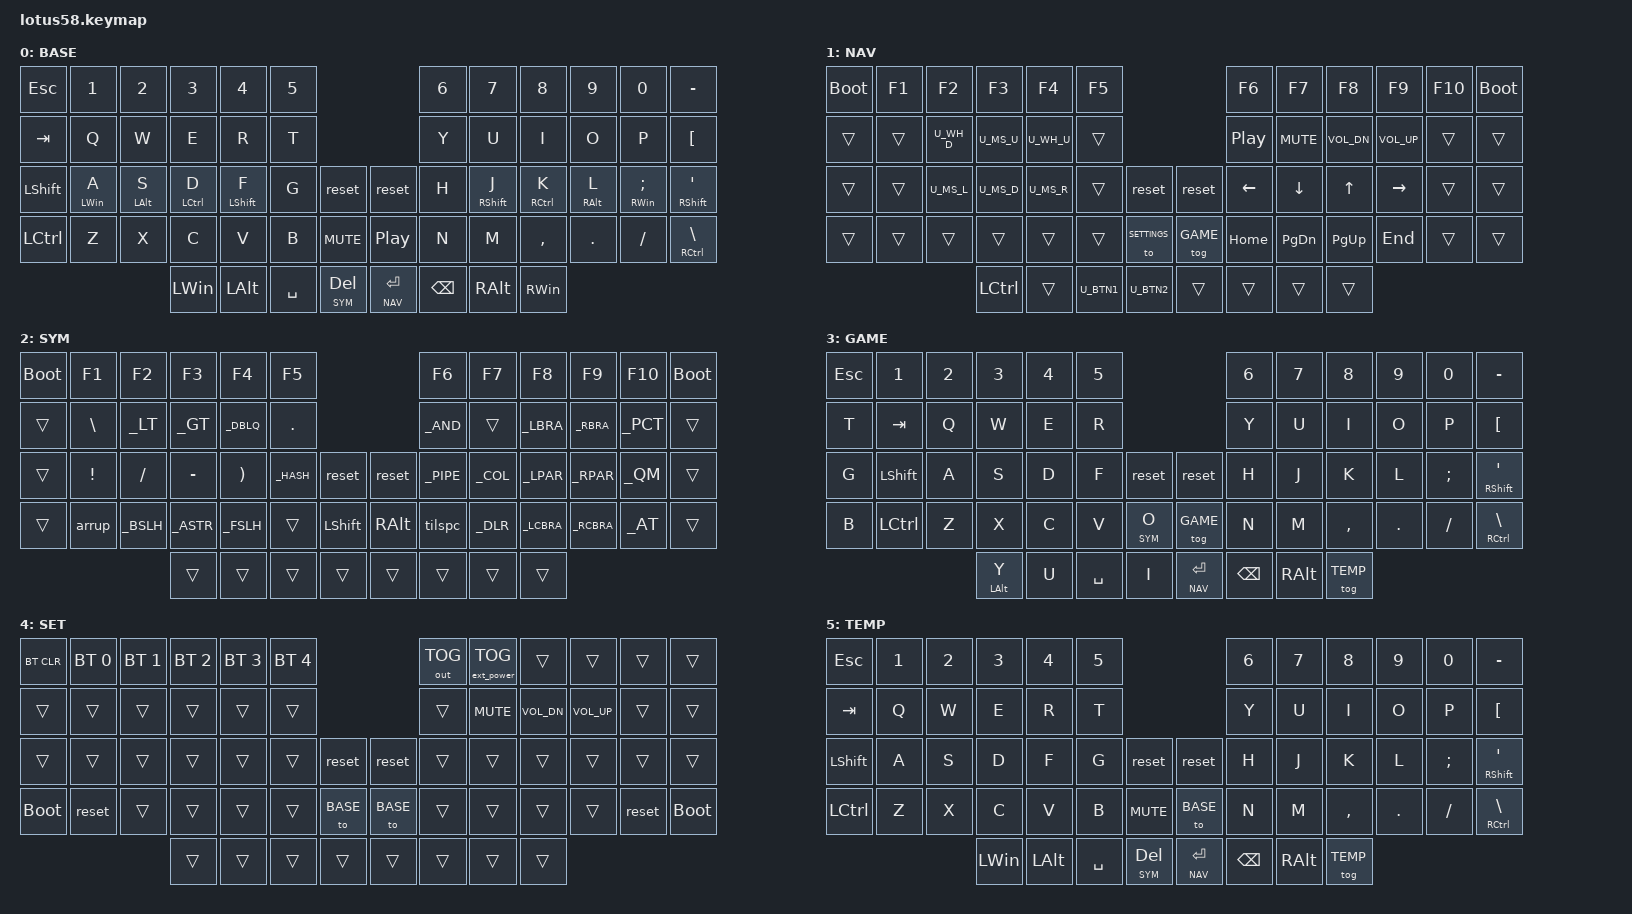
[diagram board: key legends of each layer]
/*
 * Copyright (c) 2022 The ZMK Contributors
 *
 * SPDX-License-Identifier: MIT
 */

#include <behaviors.dtsi>
#include <dt-bindings/zmk/keys.h>
#include <dt-bindings/zmk/bt.h>
#include <dt-bindings/zmk/outputs.h>
#include <dt-bindings/zmk/ext_power.h>

#include "keycodes.h"
#include "keypos.h"

#include "mouse.dtsi"

#define BASE 0
#define NAV 1
#define SYM 2
#define GAME 3
#define SETTINGS 4
#define TEMP 5

/ {
    

    macros {
        arrup: arr_up {
            label = "arr_up";
            compatible = "zmk,behavior-macro";
            #binding-cells = <0>;
            bindings
                = <&macro_tap &kp RBRC>
                , <&macro_tap &kp SPACE>
                ;
        };
        tilspc: tilde_space {
            label = "tilde_space";
            compatible = "zmk,behavior-macro";
            #binding-cells = <0>;
            bindings
                = <&macro_tap &kp _TILDE>
                , <&macro_tap &kp SPACE>
                ;
        };
    };

    behaviors {
        prog_caps: behavior_prog_caps_word {
        compatible = "zmk,behavior-caps-word";
        label = "PROG_CAPS";
        #binding-cells = <0>;
        continue-list = <FSLH LS(FSLH) RS(FSLH)>;
        };
        l_hrm: left_home_row_mod {
            compatible = "zmk,behavior-hold-tap";
            label = "LEFT_HOME_ROW_MOD";
            #binding-cells = <2>;
            flavor = "balanced";
            tapping-term-ms = <280>;
            quick-tap-ms = <175>;
            bindings = <&kp>, <&kp>;
            hold-trigger-key-positions = <MAIN_KEYS_R THUMB_KEYS_L>;
        };
        r_hrm: right_home_row_mod {
            compatible = "zmk,behavior-hold-tap";
            label = "RIGHT_HOME_ROW_MOD";
            #binding-cells = <2>;
            flavor = "balanced";
            tapping-term-ms = <280>;
            quick-tap-ms = <175>;
            bindings = <&kp>, <&kp>;
            hold-trigger-key-positions = <MAIN_KEYS_L THUMB_KEYS_R>;
        };
    };

    combos {
        compatible = "zmk,combos";

        combo_esc {
            timeout-ms = <50>;
            key-positions = <L_1_1 L_1_2>;
            layers = <0>;
            bindings = <&kp ESC>;
        };

        combo_caps_word {
            timeout-ms = <50>;
            key-positions = <L_2_4 R_2_1>;
            layers = <0>;
            bindings = <&prog_caps>;
        };

        combo_ctrl_shft_c {
            timeout-ms = <250>;
            key-positions = <R_2_2 R_2_1 L_3_3>;
            layers = <0>;
            bindings = <&kp LC(LS(C))>;
        };

        combo_ctrl_shft_v {
            timeout-ms = <250>;
            key-positions = <R_2_2 R_2_1 L_3_4>;
            layers = <0>;
            bindings = <&kp LC(LS(V))>;
        };
    };

    keymap {
        compatible = "zmk,keymap";

        base_layer {
            label = "BASE";
            bindings = <
//  _________________________________________________________________________________________________________________________________________________________________________
//  |ESC        |1          |2          |3          |4          |5          |                       |6          |7          |8          |9          |0          |+          |
    &kp ESC     &kp N1      &kp N2      &kp N3      &kp N4      &kp N5                              &kp N6      &kp N7      &kp N8      &kp N9      &kp N0      &kp MINUS
//  |-----------|-----------|-----------|-----------|-----------|-----------|                       |-----------|-----------|-----------|-----------|-----------|-----------|
//  |TAB        |Q          |W          |E          |R          |T          |                       |Y          |U          |I          |O          |P          |Å          |
    &kp TAB     &kp Q       &kp W       &kp E       &kp R       &kp T                               &kp Y       &kp U       &kp I       &kp O       &kp P       &kp LBKT
//  |-----------|-----------|-----------|-----------|-----------|-----------|                       |-----------|-----------|-----------|-----------|-----------|-----------|
//  |SHIFT      |A          |S          |D          |F          |G          |                       |H          |J          |K          |L          |Æ          |Ø          |
    &kp LSHFT   &l_hrm LWIN A       &l_hrm LALT S       &l_hrm LCTRL D       &l_hrm LSHFT F       &kp G       &reset      &reset      &kp H       &r_hrm RSHFT J       &r_hrm RCTRL K       &r_hrm RALT L       &r_hrm RWIN SEMI    &mt RSHFT SQT
//  |-----------|-----------|-----------|-----------|-----------|-----------|-----------|-----------|-----------|-----------|-----------|-----------|-----------|-----------|
//  |CTRL       |Z          |X          |C          |V          |B          |MUTE       |PLAY/PAUSE |N          |M          |,          |.          |-          |'          |
    &kp LCTRL   &kp Z       &kp X       &kp C       &kp V       &kp B       &kp C_MUTE  &kp C_PP    &kp N       &kp M       &kp COMMA   &kp DOT     &kp FSLH    &mt RCTRL BSLH
//  |-----------|-----------|-----------|-----------|-----------|-----------|-----------|-----------|-----------|-----------|-----------|-----------|-----------|-----------|
//                                      |LWIN       |LALT       |SPACE      |SYM + DEL  |NAV + ENTER|BACKSPACE  |RALT       |RWIN       |
                                        &kp LWIN    &kp LALT    &kp SPACE   &lt SYM DEL &lt NAV RET &kp BSPC    &kp RALT    &kp RWIN
//                                      |-----------|-----------|-----------|-----------|-----------|-----------|-----------|-----------|
            >;
        };

        nav_layer {
            label = "NAV";
            bindings = <
//  _________________________________________________________________________________________________________________________________________________________________________
//  |           |F1         |F2         |F3         |F4         |F5         |                       |F6         |F7         |F8         |F9         |F0         |           |
    &bootloader &kp F1      &kp F2      &kp F3      &kp F4      &kp F5                              &kp F6      &kp F7      &kp F8      &kp F9      &kp F10     &bootloader
//  |-----------|-----------|-----------|-----------|-----------|-----------|                       |-----------|-----------|-----------|-----------|-----------|-----------|
//  |           |           |           |^          |           |           |                       |PLAY/PAUSE |MUTE       |VOL DOWN   |VOL UP     |           |           |
    &trans      &trans      U_WH_D      U_MS_U      U_WH_U      &trans                              &kp C_PP    &kp C_MUTE  &kp C_VOL_DN &kp C_VOLUME_UP &trans &trans
//  |-----------|-----------|-----------|-----------|-----------|-----------|                       |-----------|-----------|-----------|-----------|-----------|-----------|
//  |           |           |<-         |v          |->         |           |                       |<-         |v          |^          |->         |           |           |
    &trans      &trans      U_MS_L      U_MS_D      U_MS_R      &trans      &reset      &reset      &kp LEFT    &kp DOWN    &kp UP      &kp RIGHT   &trans      &trans
//  |-----------|-----------|-----------|-----------|-----------|-----------|-----------|-----------|-----------|-----------|-----------|-----------|-----------|-----------|
//  |           |           |           |           |           |           |SETTINGS   |GAME       |HOME       |PAGE DOWN  |PAGE UP    |END        |           |           |
    &trans      &trans      &trans      &trans      &trans      &trans      &to SETTINGS &tog GAME  &kp HOME    &kp PG_DN   &kp PG_UP   &kp END     &trans      &trans
//  |-----------|-----------|-----------|-----------|-----------|-----------|-----------|-----------|-----------|-----------|-----------|-----------|-----------|-----------|
//                                      |CTRL       |           |m1         |m2         |           |           |           |           |
                                        &kp LCTRL   &trans      U_BTN1      U_BTN2      &trans      &trans      &trans      &trans
//                                      |-----------|-----------|-----------|-----------|-----------|-----------|-----------|-----------|
            >;
        };


        sym_layer {
            label = "SYM";
            bindings = <
//  _________________________________________________________________________________________________________________________________________________________________________
//  |           |F1         |F2         |F3         |F4         |F5         |                       |F6         |F7         |F8         |F9         |F0         |           |
    &bootloader &kp F1      &kp F2      &kp F3      &kp F4      &kp F5                              &kp F6      &kp F7      &kp F8      &kp F9      &kp F10     &bootloader
//  |-----------|-----------|-----------|-----------|-----------|-----------|                       |-----------|-----------|-----------|-----------|-----------|-----------|
//  |           |'          |<          |>          |"          |.          |                       |&          |           |(          |)          |%          |           |
    &trans      &kp BSLH    &kp _LT     &kp _GT     &kp _DBLQ   &kp DOT                             &kp _AND    &trans      &kp _LBRA   &kp _RBRA   &kp _PCT    &trans
//  |-----------|-----------|-----------|-----------|-----------|-----------|                       |-----------|-----------|-----------|-----------|-----------|-----------|
//  |           |!          |-          |+          |=          |#          |                       ||          |:          |(          |)          |?          |           |
    &trans      &kp EXCL    &kp FSLH    &kp MINUS   &kp RPAR    &kp _HASH   &reset      &reset      &kp _PIPE   &kp _COL    &kp _LPAR   &kp _RPAR   &kp _QM     &trans
//  |-----------|-----------|-----------|-----------|-----------|-----------|-----------|-----------|-----------|-----------|-----------|-----------|-----------|-----------|
//  |           |^          |/          |*          |\          |           |SHIFT      |RALT       |~          |$          |{          |}          |@          |           |
    &trans      &arrup      &kp _BSLH   &kp _ASTR   &kp _FSLH   &trans      &kp LSHFT   &kp RALT    &tilspc     &kp _DLR    &kp _LCBRA  &kp _RCBRA  &kp _AT     &trans
//  |-----------|-----------|-----------|-----------|-----------|-----------|-----------|-----------|-----------|-----------|-----------|-----------|-----------|-----------|
//                                      |           |           |           |           |           |           |           |           |
                                        &trans      &trans      &trans      &trans      &trans      &trans      &trans      &trans
//                                      |-----------|-----------|-----------|-----------|-----------|-----------|-----------|-----------|
            >;
        };

        game_layer {
            label = "GAME";
            bindings = <
//  _________________________________________________________________________________________________________________________________________________________________________
//  |ESC        |1          |2          |3          |4          |5          |                       |6          |7          |8          |9          |0          |+          |
    &kp ESC     &kp N1      &kp N2      &kp N3      &kp N4      &kp N5                              &kp N6      &kp N7      &kp N8      &kp N9      &kp N0      &kp MINUS
//  |-----------|-----------|-----------|-----------|-----------|-----------|                       |-----------|-----------|-----------|-----------|-----------|-----------|
//  |T          |TAB        |Q          |W          |E          |R          |                       |Y          |U          |I          |O          |P          |Å          |
    &kp T       &kp TAB     &kp Q       &kp W       &kp E       &kp R                               &kp Y       &kp U       &kp I       &kp O       &kp P       &kp LBKT
//  |-----------|-----------|-----------|-----------|-----------|-----------|                       |-----------|-----------|-----------|-----------|-----------|-----------|
//  |G          |SHIFT      |A          |S          |D          |F          |                       |H          |J          |K          |L          |Æ          |Ø          |
    &kp G       &kp LSHFT   &kp A       &kp S       &kp D       &kp F       &reset      &reset      &kp H       &kp J       &kp K       &kp L       &kp SEMI    &mt RSHFT SQT
//  |-----------|-----------|-----------|-----------|-----------|-----------|-----------|-----------|-----------|-----------|-----------|-----------|-----------|-----------|
//  |B          |CTRL       |Z          |X          |C          |V          |O          |BASE       |N          |M          |,          |.          |-          |'          |
    &kp B       &kp LCTRL   &kp Z       &kp X       &kp C       &kp V       &lt SYM O       &tog GAME   &kp N       &kp M       &kp COMMA   &kp DOT     &kp FSLH    &mt RCTRL BSLH
//  |-----------|-----------|-----------|-----------|-----------|-----------|-----------|-----------|-----------|-----------|-----------|-----------|-----------|-----------|
//                                      |LALT + Y   |U          |SPACE      |I          |NAV + ENTER|BACKSPACE  |RALT       |TEMP on    |
                                        &mt LALT Y  &kp U       &kp SPACE   &kp I       &lt NAV RET &kp BSPC    &kp RALT    &tog TEMP
//                                      |-----------|-----------|-----------|-----------|-----------|-----------|-----------|-----------|
            >;
        };

        settings_layer {
            label = "SET";
            bindings = <
//  _________________________________________________________________________________________________________________________________________________________________________
//  |BT clear   |BT 0       |BT 1      |BT 2        |BT 3       |BT 4       |                       |toggle bt/usb|toggle ext power |   |           |           |           |
    &bt BT_CLR &bt BT_SEL 0 &bt BT_SEL 1 &bt BT_SEL 2 &bt BT_SEL 3 &bt BT_SEL 4                     &out OUT_TOG &ext_power EP_TOG &trans &trans    &trans     &trans
//  |-----------|-----------|-----------|-----------|-----------|-----------|                       |-----------|-----------|-----------|-----------|-----------|-----------|
//  |           |           |           |^          |           |           |                       |           |MUTE       |VOL DOWN   |VOL UP     |           |           |
    &trans      &trans      &trans      &trans      &trans      &trans                              &trans      &kp C_MUTE  &kp C_VOL_DN &kp C_VOLUME_UP &trans &trans
//  |-----------|-----------|-----------|-----------|-----------|-----------|                       |-----------|-----------|-----------|-----------|-----------|-----------|
//  |           |           |           |           |           |           |                       |           |           |           |           |           |           |
    &trans      &trans      &trans      &trans      &trans      &trans      &reset      &reset      &trans      &trans      &trans      &trans      &trans      &trans
//  |-----------|-----------|-----------|-----------|-----------|-----------|-----------|-----------|-----------|-----------|-----------|-----------|-----------|-----------|
//  |           |           |           |           |           |           |                       |           |           |           |           |           |           |
    &bootloader &reset      &trans      &trans      &trans      &trans      &to BASE    &to BASE    &trans      &trans      &trans      &trans   &reset      &bootloader
//  |-----------|-----------|-----------|-----------|-----------|-----------|-----------|-----------|-----------|-----------|-----------|-----------|-----------|-----------|
//                                      |           |           |           |           |           |           |           |           |
                                        &trans      &trans      &trans      &trans      &trans      &trans      &trans      &trans
//                                      |-----------|-----------|-----------|-----------|-----------|-----------|-----------|-----------|
            >;
        };

        temp_layer {
            label = "TEMP";
            bindings = <
//  _________________________________________________________________________________________________________________________________________________________________________
//  |ESC        |1          |2          |3          |4          |5          |                       |6          |7          |8          |9          |0          |+          |
    &kp ESC     &kp N1      &kp N2      &kp N3      &kp N4      &kp N5                              &kp N6      &kp N7      &kp N8      &kp N9      &kp N0      &kp MINUS
//  |-----------|-----------|-----------|-----------|-----------|-----------|                       |-----------|-----------|-----------|-----------|-----------|-----------|
//  |TAB        |Q          |W          |E          |R          |T          |                       |Y          |U          |I          |O          |P          |Å          |
    &kp TAB     &kp Q       &kp W       &kp E       &kp R       &kp T                               &kp Y       &kp U       &kp I       &kp O       &kp P       &kp LBKT
//  |-----------|-----------|-----------|-----------|-----------|-----------|                       |-----------|-----------|-----------|-----------|-----------|-----------|
//  |SHIFT      |A          |S          |D          |F          |G          |                       |H          |J          |K          |L          |Æ          |Ø          |
    &kp LSHFT   &kp A       &kp S       &kp D       &kp F       &kp G       &reset      &reset      &kp H       &kp J       &kp K       &kp L       &kp SEMI    &mt RSHFT SQT
//  |-----------|-----------|-----------|-----------|-----------|-----------|-----------|-----------|-----------|-----------|-----------|-----------|-----------|-----------|
//  |CTRL       |Z          |X          |C          |V          |B          |           |BASE       |N          |M          |,          |.          |-          |'          |
    &kp LCTRL   &kp Z       &kp X       &kp C       &kp V       &kp B       &kp C_MUTE  &to BASE    &kp N       &kp M       &kp COMMA   &kp DOT     &kp FSLH    &mt RCTRL BSLH
//  |-----------|-----------|-----------|-----------|-----------|-----------|-----------|-----------|-----------|-----------|-----------|-----------|-----------|-----------|
//                                      |LWIN       |LALT       |SPACE      |SYM + DEL  |NAV + ENTER|BACKSPACE  |RALT       |TEMP off   |
                                        &kp LWIN    &kp LALT    &kp SPACE   &lt SYM DEL &lt NAV RET &kp BSPC    &kp RALT    &tog TEMP
//                                      |-----------|-----------|-----------|-----------|-----------|-----------|-----------|-----------|
            >;
        };

    };
        
};
